# WKUP_VTM0_CFG1 register map
Vendor: Texas Instruments
Peripheral module from a debugger description file (folder am65x).
Registers are 32-bit, access not given, no defined reset value unless marked. A register's access mark holds for its fields unless they carry their own. Offsets are as the file gives them; lines under a group give offsets from that group; [hi:lo] are bit positions; {n}, {i} and the like mark numbered series; 'fields as' and 'values as' point back to an identical list; <NAME> marks a mode.

## WKUP_VTM0_CFG1
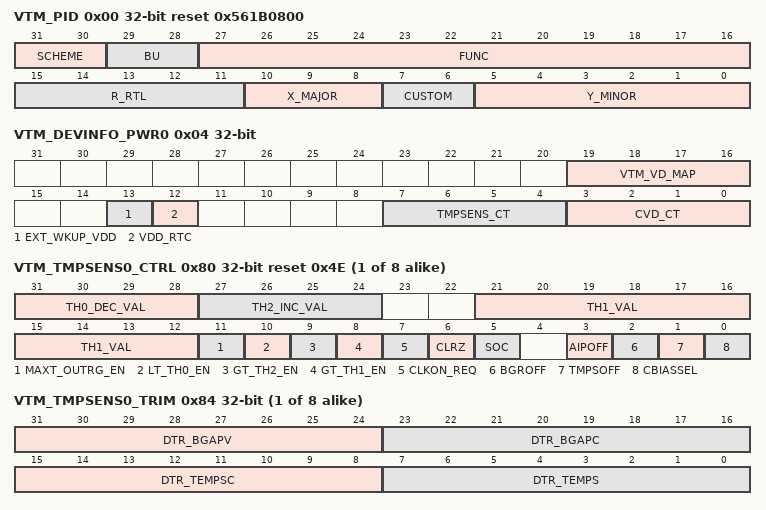
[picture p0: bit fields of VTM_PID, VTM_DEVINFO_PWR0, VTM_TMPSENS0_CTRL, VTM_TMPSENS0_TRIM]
0x00 VTM_PID ro reset 0x561B0800
  [31:30] SCHEME
  [29:28] BU — Business unit - Processors
  [27:16] FUNC — Module functional identifier - CTRL MMR
  [15:11] R_RTL — RTL revision number - actual value determined by RTL
  [10:8] X_MAJOR — Major revision number - actual value determined by RTL
  [7:6] CUSTOM — Custom revision number - actual value determined by RTL
  [5:0] Y_MINOR — Minor revision number - actual value determined by RTL
0x04 VTM_DEVINFO_PWR0 ro — Device specific voltage domain and temp sensor information register.
  [19:16] VTM_VD_MAP — Core voltage domain (cVD) global mapping 4-bit code, in the context of this SOC.
  [13] EXT_WKUP_VDD — This feature is not supported.
  [12] VDD_RTC — 0: There is NO VDD_RTC in this SOC.
  [7:4] TMPSENS_CT — Number of temperature sensors associated with this VTM.
  [3:0] CVD_CT — Number of core voltage domains in SOC.
0x08 VTM_CLK_CTRL rw — VTM clock related control MMR.
  [5:0] TSENS_CLK_DIV — Temperature sensor clock source divider selector.
0x0C VTM_MISC_CTRL rw reset 0x0 — VTM miscellaneous control bits.
  [0] ANY_MAXT_OUTRG_ALERT_EN — This bit when enable will cause, the VTM’s output therm_maxtemp_outrange_alert to be driven high, if any of the sources for the MAXT_OUTRG_ALERT, is set high.
{0x80+0x10*i} VTM_TMPSENS{i}_CTRL rw reset 0x4E (i=0..7) — Temperature Sensor{i}/Band-gap{i} control register.
  [31:28] TH0_DEC_VAL — Threshold point-0 (thpt0) decrement temp-value.
  [27:24] TH2_INC_VAL — Threshold point-2 (thpt2) incremental temp-value.
  [21:12] TH1_VAL — Threshold point-1 (thpt1) temp-value.
  [11] MAXT_OUTRG_EN — This bit enables generation of the alert in case the given temperature sensors generates a temp code above 125c.
  [10] LT_TH0_EN — Temp event/level control:
  [9] GT_TH2_EN — Temp event/level control:
  [8] GT_TH1_EN — Temp event/level control:
  [7] CLKON_REQ — This is the clock-gate enable request control of the 1-2Mhz clock used by the TMPSENS{i} (VBGAPTSV2).
  [6] CLRZ — VBGAPTSV2: Temp-Monitor control:
  [5] SOC — VBGAPTSV2: Temp-Monitor control:
  [3] AIPOFF — VBGAPTSV2:Bandgap/Temp-Monitor control:
  [2] BGROFF — VBGAPTSV2: Bandgap control:
  [1] TMPSOFF — VBGAPTSV2: Temp-Monitor control:
  [0] CBIASSEL — VBGAPTSV2:Bandgap/Temp-Monitor control:
{0x84+0x10*i} VTM_TMPSENS{i}_TRIM rw (i=0..7) — Temperature Sensor{i}/Band-gap{i} 0 trim values register.
  [31:24] DTR_BGAPV — Trim values for VBGAPTSV2:
  [23:16] DTR_BGAPC — Trim values for VBGAPTSV2:
  [15:8] DTR_TEMPSC — Trim values for VBGAPTSV2:
  [7:0] DTR_TEMPS — Trim values for VBGAPTSV2:
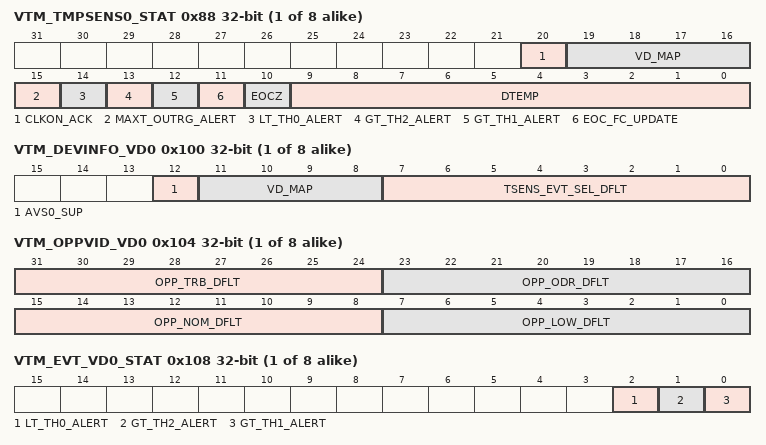
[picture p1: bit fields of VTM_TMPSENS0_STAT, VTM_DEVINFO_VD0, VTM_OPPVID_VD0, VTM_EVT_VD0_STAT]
{0x88+0x10*i} VTM_TMPSENS{i}_STAT ro (i=0..7) — Temperature Sensor{i}/Band-gap{i} Status register.
  [20] CLKON_ACK — This is the clock-gate enable acknowledge status of the 1-2Mhz clock used by the TSENS{i} (VBGAPTSV2).
  [19:16] VD_MAP — Device specific field.
  [15] MAXT_OUTRG_ALERT — This bit will be driven to a level ‘1’ for a given temperature monitor if it has its corresponding bit MAXT_OUTRG_EN == ‘1’, and the temperature reading is reporting to be outside the max temperature supported, temp&gt;125c ( DTEMP[9:0] &gt; d’946).
  [14] LT_TH0_ALERT — This field reflects the status of the LT_TH0_ALERT comparator result.
  [13] GT_TH2_ALERT — This field reflects the status of the GT_TH2_ALERT comparator result.
  [12] GT_TH1_ALERT — This field reflects the status of the GT_TH1_ALERT comparator result.
  [11] EOC_FC_UPDATE — This field is reset to ‘0’ every time VTM.
  [10] EOCZ — EOCz value from VBGAPTSV2:
  [9:0] DTEMP — DTEMP value from VBGAPTSV2:
{0x100+0x20*i} VTM_DEVINFO_VD{i} access per field (i=0..7) — Voltage domain {i} information register.
  [12] AVS0_SUP rw — Indicates if the cVD associated with this VTM’s VD{i} mmr supports AVS-Class0:
  [11:8] VD_MAP ro — Device specific field.
  [7:0] TSENS_EVT_SEL_DFLT ro — These are the default/recommended settings to be used/set in field
{0x104+0x20*i} VTM_OPPVID_VD{i} ro (i=0..7) — Voltage domain {i} VID actual code used as reference by Firmware to set the various voltage domain supply voltages. Reset defaults are sourced from efuse for each OPP.
  [31:24] OPP_TRB_DFLT — VID code that represents the required VDD value in this Voltage domain to operate at OPP_TRB (turbo).
  [23:16] OPP_ODR_DFLT — VID code that represents the required VDD value in this Voltage domain to operate at OPP_ODR (overdrive).
  [15:8] OPP_NOM_DFLT — VID code that represents the required VDD value in this Voltage domain to operate at OPP_NOM (nominal).
  [7:0] OPP_LOW_DFLT — VID code that represents the required VDD value in this Voltage domain to operate at OPP_LOW.
{0x108+0x20*i} VTM_EVT_VD{i}_STAT ro (i=0..7) — Voltage domain {i} event and control status register.
  [2] LT_TH0_ALERT — This bit reflects the status of the merged temperature alert resulting from the combination of all the similar alerts produced by the temp-monitors selected as showed in field TSENS_EVTMRG_SEL.
  [1] GT_TH2_ALERT — This bit reflects the status of the merged temperature alert resulting from the combination of all the similar alerts produced by the temp-monitors selected as showed in field TSENS_EVTMRG_SEL.
  [0] GT_TH1_ALERT — This bit reflects the status of the merged temperature alert resulting from the OR of all the similar alerts produced by the temp-monitors selected as showed in field TSENS_EVTMRG_SEL.
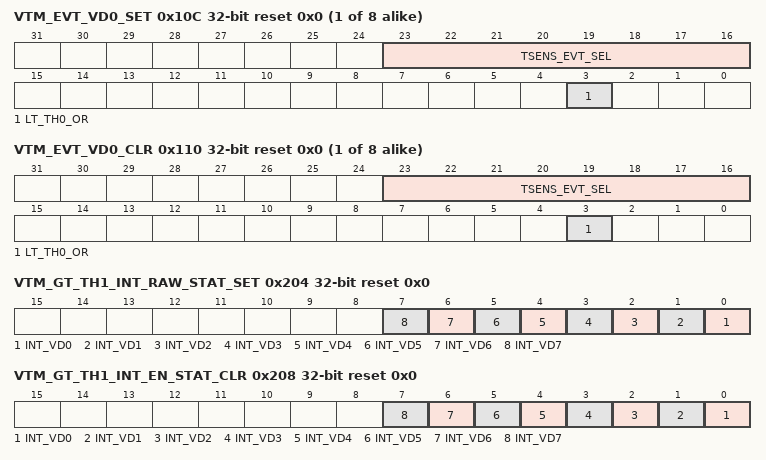
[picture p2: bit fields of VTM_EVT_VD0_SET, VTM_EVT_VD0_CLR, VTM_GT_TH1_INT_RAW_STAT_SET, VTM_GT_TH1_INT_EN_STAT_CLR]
{0x10C+0x20*i} VTM_EVT_VD{i}_SET reset 0x0 (i=0..7) — Voltage domain {i} event and control set register.
  [23:16] TSENS_EVT_SEL — In this field we select which of the event contributions of the 8-maximum possible temp-monitors controlled by this VTM will contribute to generate the merged event/alerts of this VD{i}. (access RW1S)
  [3] LT_TH0_OR — If this bit is set then the LT_TH0_alert will only become ‘0’ when all its contribution alerts from the multiple sensors selected are all ‘0’. (access RW1S)
{0x110+0x20*i} VTM_EVT_VD{i}_CLR reset 0x0 (i=0..7) — Voltage domain {i} event and control clear register.
  [23:16] TSENS_EVT_SEL — In this field we select which of the event contributions of the 8-maximum possible temp-monitors controlled by this VTM will contribute to generate the merged event/alerts of this VD{i}. (access RW1C)
  [3] LT_TH0_OR — If this bit is set then the LT_TH0_alert will only become ‘0’ when all its contribution alerts from the multiple sensors selected are all ‘0’. (access RW1C)
0x204 VTM_GT_TH1_INT_RAW_STAT_SET reset 0x0 — Interrupt RAW event status and set MMR for interrupt GT_TH1 for each voltage domain.
  [n] INT_VD{n} (n=0..7) — Write 1 to set the GT_TH1 interrupt for voltage domain {n}. Writing 0 has no effect. (access RW1S)
0x208 VTM_GT_TH1_INT_EN_STAT_CLR reset 0x0 — Enabled interrupt event status and clear MMR for interrupt GT_TH1 per voltage domain.
  [n] INT_VD{n} (n=0..7) — Write 1 to clear the pending GT_TH1 interrupt for voltage domain {n}. Writing 0 has no effect. (access RW1C)
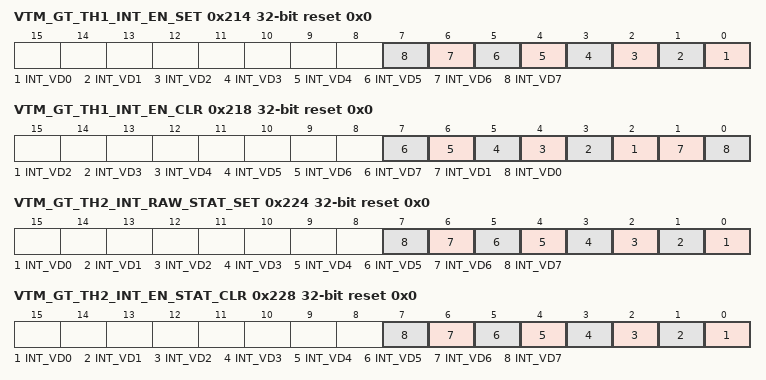
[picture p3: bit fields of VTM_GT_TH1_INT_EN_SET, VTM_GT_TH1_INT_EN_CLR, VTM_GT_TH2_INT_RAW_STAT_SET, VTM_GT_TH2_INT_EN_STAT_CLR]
0x214 VTM_GT_TH1_INT_EN_SET reset 0x0 — Enable set MMR for interrupt GT_TH1 for each voltage domain.
  [n] INT_VD{n} (n=0..7) — Write 1 to set the GT_TH1 interrupt enable for voltage domain {n}. Writing 0 has no effect. (access RW1S)
0x218 VTM_GT_TH1_INT_EN_CLR reset 0x0 — Enable clear MMR for interrupt GT_TH1 for each voltage domain.
  [n] INT_VD{n} (n=2..7) — Write 1 to clear the GT_TH1 interrupt enable for voltage domain {n}. Writing 0 has no effect. (access RW1C)
  [1] INT_VD1 — Write 1 to clear the GT_TH1 interrupt enable for voltage domain 1 . Writing 0 has no effect. (access RW1C)
  [0] INT_VD0 — Write 1 to clear the GT_TH1 interrupt enable for voltage domain 0. Writing 0 has no effect. (access RW1C)
0x224 VTM_GT_TH2_INT_RAW_STAT_SET reset 0x0 — Interrupt RAW event status and set MMR for interrupt GT_TH2 for each voltage domain.
  [n] INT_VD{n} (n=0..7) — Write 1 to set the GT_TH2 interrupt for voltage domain {n}. Writing 0 has no effect. (access RW1S)
0x228 VTM_GT_TH2_INT_EN_STAT_CLR reset 0x0 — Enabled interrupt event status and clear MMR for interrupt GT_TH2 per voltage domain.
  [n] INT_VD{n} (n=0..7) — Write 1 to clear the pending GT_TH2 interrupt for voltage domain {n}. Writing 0 has no effect. (access RW1C)
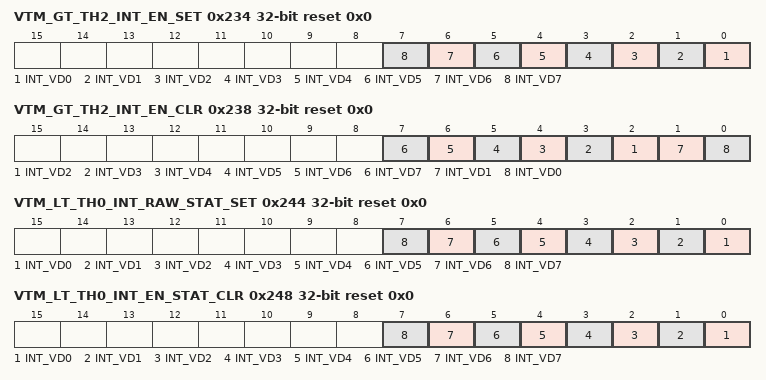
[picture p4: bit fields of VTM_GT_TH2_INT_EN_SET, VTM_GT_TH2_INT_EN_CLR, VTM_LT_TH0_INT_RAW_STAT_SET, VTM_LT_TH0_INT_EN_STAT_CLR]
0x234 VTM_GT_TH2_INT_EN_SET reset 0x0 — Enable set MMR for interrupt GT_TH2 for each voltage domain.
  [n] INT_VD{n} (n=0..7) — Write 1 to set the GT_TH2 interrupt enable for voltage domain {n}. Writing 0 has no effect. (access RW1S)
0x238 VTM_GT_TH2_INT_EN_CLR reset 0x0 — Enable clear MMR for interrupt GT_TH2 for each voltage domain.
  [n] INT_VD{n} (n=2..7) — Write 1 to clear the GT_TH2 interrupt enable for voltage domain {n}. Writing 0 has no effect. (access RW1C)
  [1] INT_VD1 — Write 1 to clear the GT_TH2 interrupt enable for voltage domain 1 . Writing 0 has no effect. (access RW1C)
  [0] INT_VD0 — Write 1 to clear the GT_TH2 interrupt enable for voltage domain 0. Writing 0 has no effect. (access RW1C)
0x244 VTM_LT_TH0_INT_RAW_STAT_SET reset 0x0 — Interrupt RAW event status and set MMR for interrupt LT_TH0 for each voltage domain.
  [n] INT_VD{n} (n=0..7) — Write 1 to set the LT_TH0 interrupt for voltage domain {n}. Writing 0 has no effect. (access RW1S)
0x248 VTM_LT_TH0_INT_EN_STAT_CLR reset 0x0 — Enabled interrupt event status and clear MMR for interrupt LT_TH0 per voltage domain.
  [n] INT_VD{n} (n=0..7) — Write 1 to clear the pending LT_TH0 interrupt for voltage domain {n}. Writing 0 has no effect. (access RW1C)
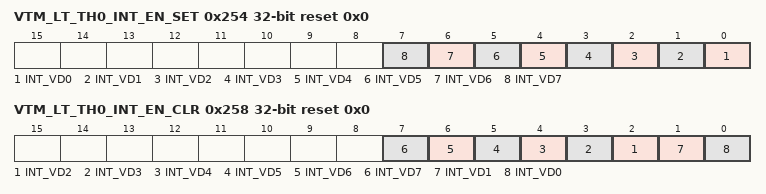
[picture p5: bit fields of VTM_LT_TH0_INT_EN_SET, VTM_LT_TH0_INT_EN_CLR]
0x254 VTM_LT_TH0_INT_EN_SET reset 0x0 — Enable set MMR for interrupt LT_TH0 for each voltage domain.
  [n] INT_VD{n} (n=0..7) — Write 1 to set the LT_TH0 interrupt enable for voltage domain {n}. Writing 0 has no effect. (access RW1S)
0x258 VTM_LT_TH0_INT_EN_CLR reset 0x0 — Enable clear MMR for interrupt LT_TH0 for each voltage domain.
  [n] INT_VD{n} (n=2..7) — Write 1 to clear the LT_TH0 interrupt enable for voltage domain {n}. Writing 0 has no effect. (access RW1C)
  [1] INT_VD1 — Write 1 to clear the LT_TH0 interrupt enable for voltage domain 1 . Writing 0 has no effect. (access RW1C)
  [0] INT_VD0 — Write 1 to clear the LT_TH0 interrupt enable for voltage domain 0. Writing 0 has no effect. (access RW1C)
